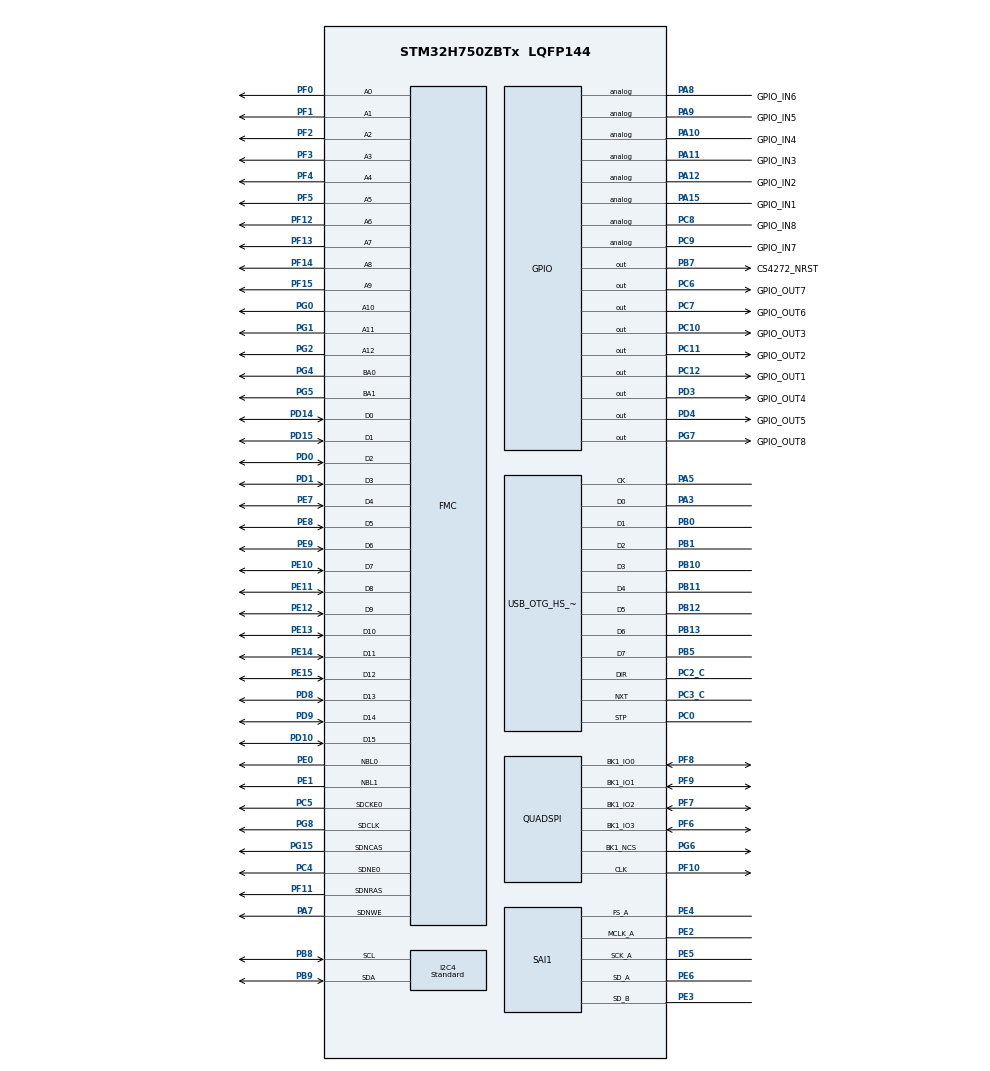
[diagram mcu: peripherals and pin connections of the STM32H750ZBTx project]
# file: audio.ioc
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CORTEX_M7.AccessPermission_S-Cortex_Memory_Protection_Unit_Region1_Settings_S=MPU_REGION_FULL_ACCESS
CORTEX_M7.AccessPermission_Spec=MPU_REGION_FULL_ACCESS
CORTEX_M7.BaseAddress_S-Cortex_Memory_Protection_Unit_Region1_Settings_S=0x24000000 
CORTEX_M7.BaseAddress_Spec=0x90000000
CORTEX_M7.CPU_DCache=Enabled
CORTEX_M7.CPU_ICache=Enabled
CORTEX_M7.DisableExec_S-Cortex_Memory_Protection_Unit_Region1_Settings_S=MPU_INSTRUCTION_ACCESS_ENABLE
CORTEX_M7.DisableExec_Spec=MPU_INSTRUCTION_ACCESS_ENABLE
CORTEX_M7.Enable_S-Cortex_Memory_Protection_Unit_Region1_Settings_S=MPU_REGION_ENABLE
CORTEX_M7.IsBufferable_Spec=MPU_ACCESS_BUFFERABLE
CORTEX_M7.IsCacheable_Spec=MPU_ACCESS_CACHEABLE
CORTEX_M7.IsShareable_S-Cortex_Memory_Protection_Unit_Region1_Settings_S=MPU_ACCESS_SHAREABLE
CORTEX_M7.IsShareable_Spec=MPU_ACCESS_NOT_SHAREABLE
CORTEX_M7.Size_S-Cortex_Memory_Protection_Unit_Region1_Settings_S=MPU_REGION_SIZE_512KB
CORTEX_M7.Size_Spec=MPU_REGION_SIZE_16MB
CORTEX_M7.SubRegionDisable_Spec=0x0
CORTEX_M7.TypeExtField_S-Cortex_Memory_Protection_Unit_Region1_Settings_S=MPU_TEX_LEVEL1
CORTEX_M7.TypeExtField_Spec=MPU_TEX_LEVEL1
CORTEX_M7.default_mode_Activation=1
Dma.Request0=SAI1_B
Dma.Request1=SAI1_A
Dma.SAI1_A.1.Direction=DMA_MEMORY_TO_PERIPH
Dma.SAI1_A.1.EventEnable=DISABLE
Dma.SAI1_A.1.FIFOMode=DMA_FIFOMODE_DISABLE
Dma.SAI1_A.1.Instance=DMA1_Stream1
Dma.SAI1_A.1.MemDataAlignment=DMA_MDATAALIGN_WORD
Dma.SAI1_A.1.MemInc=DMA_MINC_ENABLE
Dma.SAI1_A.1.Mode=DMA_CIRCULAR
Dma.SAI1_A.1.PeriphDataAlignment=DMA_PDATAALIGN_WORD
Dma.SAI1_A.1.PeriphInc=DMA_PINC_DISABLE
Dma.SAI1_A.1.Polarity=HAL_DMAMUX_REQ_GEN_RISING
Dma.SAI1_A.1.Priority=DMA_PRIORITY_VERY_HIGH
Dma.SAI1_A.1.RequestNumber=1
Dma.SAI1_A.1.SignalID=NONE
Dma.SAI1_A.1.SyncEnable=DISABLE
Dma.SAI1_A.1.SyncPolarity=HAL_DMAMUX_SYNC_NO_EVENT
Dma.SAI1_A.1.SyncRequestNumber=1
Dma.SAI1_A.1.SyncSignalID=NONE
Dma.SAI1_B.0.Direction=DMA_PERIPH_TO_MEMORY
Dma.SAI1_B.0.EventEnable=DISABLE
Dma.SAI1_B.0.FIFOMode=DMA_FIFOMODE_DISABLE
Dma.SAI1_B.0.Instance=DMA1_Stream0
Dma.SAI1_B.0.MemDataAlignment=DMA_MDATAALIGN_WORD
Dma.SAI1_B.0.MemInc=DMA_MINC_ENABLE
Dma.SAI1_B.0.Mode=DMA_CIRCULAR
Dma.SAI1_B.0.PeriphDataAlignment=DMA_PDATAALIGN_WORD
Dma.SAI1_B.0.PeriphInc=DMA_PINC_DISABLE
Dma.SAI1_B.0.Polarity=HAL_DMAMUX_REQ_GEN_RISING
Dma.SAI1_B.0.Priority=DMA_PRIORITY_VERY_HIGH
Dma.SAI1_B.0.RequestNumber=1
Dma.SAI1_B.0.SignalID=NONE
Dma.SAI1_B.0.SyncEnable=DISABLE
Dma.SAI1_B.0.SyncPolarity=HAL_DMAMUX_SYNC_NO_EVENT
Dma.SAI1_B.0.SyncRequestNumber=1
Dma.SAI1_B.0.SyncSignalID=NONE
FMC.CASLatency1=FMC_SDRAM_CAS_LATENCY_2
FMC.ColumnBitsNumber1=FMC_SDRAM_COLUMN_BITS_NUM_9
FMC.ExitSelfRefreshDelay1=8
FMC.LoadToActiveDelay1=2
FMC.RCDDelay1=2
FMC.RPDelay1=2
FMC.RPDelay2=2
FMC.ReadBurst1=FMC_SDRAM_RBURST_ENABLE
FMC.ReadBurst2=FMC_SDRAM_RBURST_ENABLE
FMC.ReadPipeDelay1=FMC_SDRAM_RPIPE_DELAY_2
FMC.ReadPipeDelay2=FMC_SDRAM_RPIPE_DELAY_2
FMC.RowCycleDelay1=6
FMC.RowCycleDelay2=6
FMC.SDClockPeriod1=FMC_SDRAM_CLOCK_PERIOD_2
FMC.SDClockPeriod2=FMC_SDRAM_CLOCK_PERIOD_2
FMC.SelfRefreshTime1=5
FMC.WriteRecoveryTime1=3
I2C4.I2C_Speed_Mode=I2C_Standard
I2C4.Speed=100
I2C4.Timing=0x307075B1
Mcu.Family=STM32H7
Mcu.Name=STM32H750ZBTx
Mcu.Package=LQFP144
NVIC.DMA1_Stream0_IRQn=true\:0\:0\:false\:false\:true\:false\:true\:true
NVIC.DMA1_Stream1_IRQn=true\:0\:0\:false\:false\:true\:false\:true\:true
NVIC.OTG_HS_EP1_IN_IRQn=true\:0\:0\:false\:false\:true\:true\:true\:true
NVIC.OTG_HS_EP1_OUT_IRQn=true\:0\:0\:false\:false\:true\:true\:true\:true
NVIC.OTG_HS_IRQn=true\:0\:0\:false\:false\:true\:false\:true\:true
NVIC.PriorityGroup=NVIC_PRIORITYGROUP_4
PA10.GPIO_Label=GPIO_IN4
PA10.Signal=GPIO_Analog
PA11.GPIO_Label=GPIO_IN3
PA11.Signal=GPIO_Analog
PA12.GPIO_Label=GPIO_IN2
PA12.Signal=GPIO_Analog
PA13\ (JTMS/SWDIO).Mode=Trace_Asynchronous_SW
PA13\ (JTMS/SWDIO).Signal=DEBUG_JTMS-SWDIO
PA14\ (JTCK/SWCLK).Mode=Trace_Asynchronous_SW
PA14\ (JTCK/SWCLK).Signal=DEBUG_JTCK-SWCLK
PA15\ (JTDI).GPIO_Label=GPIO_IN1
PA15\ (JTDI).Signal=GPIO_Analog
PA3.Mode=Device_HS
PA3.Signal=USB_OTG_HS_ULPI_D0
PA5.Mode=Device_HS
PA5.Signal=USB_OTG_HS_ULPI_CK
PA7.Signal=FMC_SDNWE
PA8.GPIO_Label=GPIO_IN6
PA8.Signal=GPIO_Analog
PA9.GPIO_Label=GPIO_IN5
PA9.Signal=GPIO_Analog
PB0.Mode=Device_HS
PB0.Signal=USB_OTG_HS_ULPI_D1
PB1.Mode=Device_HS
PB1.Signal=USB_OTG_HS_ULPI_D2
PB10.Mode=Device_HS
PB10.Signal=USB_OTG_HS_ULPI_D3
PB11.Mode=Device_HS
PB11.Signal=USB_OTG_HS_ULPI_D4
PB12.Mode=Device_HS
PB12.Signal=USB_OTG_HS_ULPI_D5
PB13.Mode=Device_HS
PB13.Signal=USB_OTG_HS_ULPI_D6
PB3\ (JTDO/TRACESWO).Mode=Trace_Asynchronous_SW
PB3\ (JTDO/TRACESWO).Signal=DEBUG_JTDO-SWO
PB5.Mode=Device_HS
PB5.Signal=USB_OTG_HS_ULPI_D7
PB7.GPIO_Label=CS4272_NRST
PB7.Signal=GPIO_Output
PB8.Mode=I2C
PB8.Signal=I2C4_SCL
PB9.Mode=I2C
PB9.Signal=I2C4_SDA
PC0.Mode=Device_HS
PC0.Signal=USB_OTG_HS_ULPI_STP
PC10.GPIO_Label=GPIO_OUT3
PC10.Signal=GPIO_Output
PC11.GPIO_Label=GPIO_OUT2
PC11.Signal=GPIO_Output
PC12.GPIO_Label=GPIO_OUT1
PC12.Signal=GPIO_Output
PC2_C.Mode=Device_HS
PC2_C.Signal=USB_OTG_HS_ULPI_DIR
PC3_C.Mode=Device_HS
PC3_C.Signal=USB_OTG_HS_ULPI_NXT
PC4.Mode=SdramChipSelect1_1
PC4.Signal=FMC_SDNE0
PC5.Mode=SdramChipSelect1_1
PC5.Signal=FMC_SDCKE0
PC6.GPIO_Label=GPIO_OUT7
PC6.Signal=GPIO_Output
PC7.GPIO_Label=GPIO_OUT6
PC7.Signal=GPIO_Output
PC8.GPIO_Label=GPIO_IN8
PC8.Signal=GPIO_Analog
PC9.GPIO_Label=GPIO_IN7
PC9.Signal=GPIO_Analog
PD0.Signal=FMC_D2_DA2
PD1.Signal=FMC_D3_DA3
PD10.Signal=FMC_D15_DA15
PD14.Signal=FMC_D0_DA0
PD15.Signal=FMC_D1_DA1
PD3.GPIO_Label=GPIO_OUT4
PD3.Signal=GPIO_Output
PD4.GPIO_Label=GPIO_OUT5
PD4.Signal=GPIO_Output
PD8.Signal=FMC_D13_DA13
PD9.Signal=FMC_D14_DA14
PE0.Signal=FMC_NBL0
PE1.Signal=FMC_NBL1
PE10.Signal=FMC_D7_DA7
PE11.Signal=FMC_D8_DA8
PE12.Signal=FMC_D9_DA9
PE13.Signal=FMC_D10_DA10
PE14.Signal=FMC_D11_DA11
PE15.Signal=FMC_D12_DA12
PE2.GPIO_Mode=GPIO_MODE_AF_PP
PE2.GPIO_Speed=GPIO_SPEED_FREQ_VERY_HIGH
PE2.Mode=SAI_A_MasterWithClock
PE2.Signal=SAI1_MCLK_A
PE3.GPIO_Mode=GPIO_MODE_AF_PP
PE3.GPIO_Speed=GPIO_SPEED_FREQ_VERY_HIGH
PE3.Mode=SAI_B_SyncSlave
PE3.Signal=SAI1_SD_B
PE4.GPIO_Mode=GPIO_MODE_AF_PP
PE4.GPIO_Speed=GPIO_SPEED_FREQ_VERY_HIGH
PE4.Mode=SAI_A_MasterWithClock
PE4.Signal=SAI1_FS_A
PE5.GPIO_Mode=GPIO_MODE_AF_PP
PE5.GPIO_Speed=GPIO_SPEED_FREQ_VERY_HIGH
PE5.Mode=SAI_A_MasterWithClock
PE5.Signal=SAI1_SCK_A
PE6.GPIO_Mode=GPIO_MODE_AF_PP
PE6.GPIO_Speed=GPIO_SPEED_FREQ_VERY_HIGH
PE6.Mode=SAI_A_MasterWithClock
PE6.Signal=SAI1_SD_A
PE7.Signal=FMC_D4_DA4
PE8.Signal=FMC_D5_DA5
PE9.Signal=FMC_D6_DA6
PF0.Signal=FMC_A0
PF1.Signal=FMC_A1
PF10.GPIO_Speed=GPIO_SPEED_FREQ_VERY_HIGH
PF10.Mode=Single Bank 1
PF10.Signal=QUADSPI_CLK
PF11.Signal=FMC_SDNRAS
PF12.Signal=FMC_A6
PF13.Signal=FMC_A7
PF14.Signal=FMC_A8
PF15.Signal=FMC_A9
PF2.Signal=FMC_A2
PF3.Signal=FMC_A3
PF4.Signal=FMC_A4
PF5.Signal=FMC_A5
PF6.GPIO_Speed=GPIO_SPEED_FREQ_VERY_HIGH
PF6.Mode=Single Bank 1
PF6.Signal=QUADSPI_BK1_IO3
PF7.GPIO_Speed=GPIO_SPEED_FREQ_VERY_HIGH
PF7.Mode=Single Bank 1
PF7.Signal=QUADSPI_BK1_IO2
PF8.GPIO_Speed=GPIO_SPEED_FREQ_VERY_HIGH
PF8.Mode=Single Bank 1
PF8.Signal=QUADSPI_BK1_IO0
PF9.GPIO_Speed=GPIO_SPEED_FREQ_VERY_HIGH
PF9.Mode=Single Bank 1
PF9.Signal=QUADSPI_BK1_IO1
PG0.Signal=FMC_A10
PG1.Signal=FMC_A11
PG15.Signal=FMC_SDNCAS
PG2.Signal=FMC_A12
PG4.Signal=FMC_A14_BA0
PG5.Signal=FMC_A15_BA1
PG6.GPIO_Speed=GPIO_SPEED_FREQ_VERY_HIGH
PG6.Mode=Single Bank 1
PG6.Signal=QUADSPI_BK1_NCS
PG7.GPIO_Label=GPIO_OUT8
PG7.Signal=GPIO_Output
PG8.Signal=FMC_SDCLK
PH0-OSC_IN\ (PH0).Mode=HSE-External-Clock-Source
PH0-OSC_IN\ (PH0).Signal=RCC_OSC_IN
ProjectManager.HeapSize=0x200
ProjectManager.StackSize=0x400
ProjectManager.TargetToolchain=STM32CubeIDE
QUADSPI.ChipSelectHighTime=QSPI_CS_HIGH_TIME_2_CYCLE
QUADSPI.ClockPrescaler=2
QUADSPI.FifoThreshold=4
QUADSPI.FlashSize=23
QUADSPI.SampleShifting=QSPI_SAMPLE_SHIFTING_HALFCYCLE
RCC.ADCFreq_Value=100000000
RCC.APB1Freq_Value=120000000
RCC.APB2Freq_Value=120000000
RCC.APB3Freq_Value=120000000
RCC.APB4Freq_Value=120000000
RCC.CortexFreq_Value=480000000
RCC.D1PPRE=RCC_APB3_DIV2
RCC.D2PPRE1=RCC_APB1_DIV2
RCC.D2PPRE2=RCC_APB2_DIV2
RCC.D3PPRE=RCC_APB4_DIV2
RCC.DIVM1=5
RCC.DIVM2=2
RCC.DIVM3=5
RCC.DIVN1=192
RCC.DIVN2=16
RCC.DIVN3=49
RCC.DIVP3=20
RCC.DIVQ1=15
RCC.DIVQ3=5
RCC.DIVR2=1
RCC.DIVR3=30
RCC.FMCCLockSelection=RCC_FMCCLKSOURCE_PLL2
RCC.HCLKFreq_Value=240000000
RCC.HPRE=RCC_HCLK_DIV2
RCC.HSE_VALUE=25000000
RCC.PLL2FRACN=0
RCC.PLL3FRACN=1246
RCC.PLLFRACN=0
RCC.QSPICLockSelection=RCC_QSPICLKSOURCE_PLL2
RCC.SAI1CLockSelection=RCC_SAI1CLKSOURCE_PLL3
RCC.SYSCLKFreq_VALUE=480000000
RCC.SYSCLKSource=RCC_SYSCLKSOURCE_PLLCLK
RCC.USBFreq_Value=64000000
SAI1.AudioFrequency-SAI_A_MasterWithClock=SAI_AUDIO_FREQUENCY_48K
SAI1.BasicDataSize-SAI_A_MasterWithClock=SAI_PROTOCOL_DATASIZE_24BIT
SAI1.BasicDataSize-SAI_B_SyncSlave=SAI_PROTOCOL_DATASIZE_24BIT
SAI1.ErrorAudioFreq-SAI_A_MasterWithClock=0.0 %
SAI1.FIFOThreshold-SAI_A_MasterWithClock=SAI_FIFOTHRESHOLD_EMPTY
SAI1.FIFOThreshold-SAI_B_SyncSlave=SAI_FIFOTHRESHOLD_EMPTY
SAI1.InitProtocol-SAI_A_MasterWithClock=Enable
SAI1.InitProtocol-SAI_B_SyncSlave=Enable
SAI1.Instance-SAI_A_MasterWithClock=SAI$Index_Block_A
SAI1.Instance-SAI_B_SyncSlave=SAI$Index_Block_B
SAI1.MClockEnable-SAI_A_MasterWithClock=SAI_MASTERCLOCK_ENABLE
SAI1.NoDivider-SAI_A_MasterWithClock=SAI_MCK_OVERSAMPLING_DISABLE
SAI1.OutputDrive-SAI_A_MasterWithClock=SAI_OUTPUTDRIVE_DISABLE
SAI1.RealAudioFreq-SAI_A_MasterWithClock=48.0 KHz
SAI1.VirtualMode-SAI_A_MasterWithClock=VM_MASTER
SAI1.VirtualMode-SAI_B_SyncSlave=VM_SLAVE
SAI1.VirtualProtocol-SAI_A_BASIC=VM_BASIC_PROTOCOL
SAI1.VirtualProtocol-SAI_B_BASIC=VM_BASIC_PROTOCOL
SH.FMC_A0.0=FMC_A0,13b-sda1
SH.FMC_A1.0=FMC_A1,13b-sda1
SH.FMC_A10.0=FMC_A10,13b-sda1
SH.FMC_A11.0=FMC_A11,13b-sda1
SH.FMC_A12.0=FMC_A12,13b-sda1
SH.FMC_A14_BA0.0=FMC_BA0,FourSdramBanks1
SH.FMC_A15_BA1.0=FMC_BA1,FourSdramBanks1
SH.FMC_A2.0=FMC_A2,13b-sda1
SH.FMC_A3.0=FMC_A3,13b-sda1
SH.FMC_A4.0=FMC_A4,13b-sda1
SH.FMC_A5.0=FMC_A5,13b-sda1
SH.FMC_A6.0=FMC_A6,13b-sda1
SH.FMC_A7.0=FMC_A7,13b-sda1
SH.FMC_A8.0=FMC_A8,13b-sda1
SH.FMC_A9.0=FMC_A9,13b-sda1
SH.FMC_D0_DA0.0=FMC_D0,sd-16b-d1
SH.FMC_D10_DA10.0=FMC_D10,sd-16b-d1
SH.FMC_D11_DA11.0=FMC_D11,sd-16b-d1
SH.FMC_D12_DA12.0=FMC_D12,sd-16b-d1
SH.FMC_D13_DA13.0=FMC_D13,sd-16b-d1
SH.FMC_D14_DA14.0=FMC_D14,sd-16b-d1
SH.FMC_D15_DA15.0=FMC_D15,sd-16b-d1
SH.FMC_D1_DA1.0=FMC_D1,sd-16b-d1
SH.FMC_D2_DA2.0=FMC_D2,sd-16b-d1
SH.FMC_D3_DA3.0=FMC_D3,sd-16b-d1
SH.FMC_D4_DA4.0=FMC_D4,sd-16b-d1
SH.FMC_D5_DA5.0=FMC_D5,sd-16b-d1
SH.FMC_D6_DA6.0=FMC_D6,sd-16b-d1
SH.FMC_D7_DA7.0=FMC_D7,sd-16b-d1
SH.FMC_D8_DA8.0=FMC_D8,sd-16b-d1
SH.FMC_D9_DA9.0=FMC_D9,sd-16b-d1
SH.FMC_NBL0.0=FMC_NBL0,Sd2ByteEnable1
SH.FMC_NBL1.0=FMC_NBL1,Sd2ByteEnable1
SH.FMC_SDCLK.0=FMC_SDCLK,13b-sda1
SH.FMC_SDNCAS.0=FMC_SDNCAS,13b-sda1
SH.FMC_SDNRAS.0=FMC_SDNRAS,13b-sda1
SH.FMC_SDNWE.0=FMC_SDNWE,13b-sda1
USB_DEVICE.CLASS_NAME_HS=MSC
USB_DEVICE.VirtualMode-MSC_HS=Msc
USB_DEVICE.VirtualModeHS=Msc_HS
USB_OTG_HS.VirtualMode-Device_HS=Device_HS
USB_OTG_HS.dma_enable-Device_HS=ENABLE
VP_MEMORYMAP_VS_MEMORYMAP.Mode=CurAppReg
VP_SAI1_VP_$IpInstance_SAIA_SAI_BASIC.Mode=SAI_A_BASIC
VP_SAI1_VP_$IpInstance_SAIB_SAI_BASIC.Mode=SAI_B_BASIC
VP_USB_DEVICE_VS_USB_DEVICE_MSC_HS.Mode=MSC_HS
board=custom

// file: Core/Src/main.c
/* USER CODE BEGIN Header */
/**
  ******************************************************************************
  * @file           : main.c
  * @brief          : Main program body
  ******************************************************************************
  * @attention
  *
  * Copyright (c) 2026 STMicroelectronics.
  * All rights reserved.
  *
  * This software is licensed under terms that can be found in the LICENSE file
  * in the root directory of this software component.
  * If no LICENSE file comes with this software, it is provided AS-IS.
  *
  ******************************************************************************
  */
/* USER CODE END Header */
#include "main.h"
#include "dma.h"
#include "i2c.h"
#include "quadspi.h"
#include "sai.h"
#include "usb_device.h"
#include "gpio.h"
#include "fmc.h"

/* USER CODE BEGIN Includes */
#include "cs4272.h"
#include "w9825g6kh6.h"
/* USER CODE END Includes */

void SystemClock_Config(void);
void PeriphCommonClock_Config(void);
static void MPU_Config(void);

int main(void)
{

  /* USER CODE BEGIN 1 */

  /* disabled by the boot loader */
  __enable_irq();

  /* USER CODE END 1 */

  /* MPU Configuration--------------------------------------------------------*/
  MPU_Config();

  /* Enable the CPU Cache */

  /* Enable I-Cache---------------------------------------------------------*/
  SCB_EnableICache();

  /* Enable D-Cache---------------------------------------------------------*/
  SCB_EnableDCache();

  /* MCU Configuration--------------------------------------------------------*/

  /* Reset of all peripherals, Initializes the Flash interface and the Systick. */
  HAL_Init();

  /* Configure the system clock */
  SystemClock_Config();

  /* Configure the peripherals common clocks */
  PeriphCommonClock_Config();

  /* Initialize all configured peripherals */
  MX_GPIO_Init();
  MX_DMA_Init();
  MX_FMC_Init();
  MX_I2C4_Init();
  MX_SAI1_Init();
  MX_USB_DEVICE_Init();
  //MX_QUADSPI_Init();
  /* USER CODE BEGIN 2 */

  FMC_Init();
  SDRAM_Test();

  __HAL_RCC_SAI1_CLK_ENABLE();
  __HAL_SAI_ENABLE(&hsai_BlockA1);

  HAL_Delay(10);

  if (CS4272_Init() != HAL_OK) {
      Error_Handler();
  }

  if (HAL_SAI_Receive_DMA(&hsai_BlockB1, (uint8_t *)rx_buffer, BUFFER_SIZE) != HAL_OK) {
      Error_Handler();
  }

  if (HAL_SAI_Transmit_DMA(&hsai_BlockA1, (uint8_t *)tx_buffer, BUFFER_SIZE) != HAL_OK) {
      Error_Handler();
  }

  /* USER CODE END 2 */

  /* Infinite loop */
  while (1)
  {

  }
}

void SystemClock_Config(void)
{
  RCC_OscInitTypeDef RCC_OscInitStruct = {0};
  RCC_ClkInitTypeDef RCC_ClkInitStruct = {0};

  /** Supply configuration update enable
  */
  HAL_PWREx_ConfigSupply(PWR_LDO_SUPPLY);

  /** Configure the main internal regulator output voltage
  */
  __HAL_PWR_VOLTAGESCALING_CONFIG(PWR_REGULATOR_VOLTAGE_SCALE0);

  while(!__HAL_PWR_GET_FLAG(PWR_FLAG_VOSRDY)) {}

  /** Initializes the RCC Oscillators according to the specified parameters
  * in the RCC_OscInitTypeDef structure.
  */
  RCC_OscInitStruct.OscillatorType = RCC_OSCILLATORTYPE_HSE;
  RCC_OscInitStruct.HSEState = RCC_HSE_BYPASS;
  RCC_OscInitStruct.PLL.PLLState = RCC_PLL_ON;
  RCC_OscInitStruct.PLL.PLLSource = RCC_PLLSOURCE_HSE;
  RCC_OscInitStruct.PLL.PLLM = 5;
  RCC_OscInitStruct.PLL.PLLN = 192;
  RCC_OscInitStruct.PLL.PLLP = 2;
  RCC_OscInitStruct.PLL.PLLQ = 15;
  RCC_OscInitStruct.PLL.PLLR = 2;
  RCC_OscInitStruct.PLL.PLLRGE = RCC_PLL1VCIRANGE_2;
  RCC_OscInitStruct.PLL.PLLVCOSEL = RCC_PLL1VCOWIDE;
  RCC_OscInitStruct.PLL.PLLFRACN = 0;
  if (HAL_RCC_OscConfig(&RCC_OscInitStruct) != HAL_OK)
  {
    Error_Handler();
  }

  /** Initializes the CPU, AHB and APB buses clocks
  */
  RCC_ClkInitStruct.ClockType = RCC_CLOCKTYPE_HCLK|RCC_CLOCKTYPE_SYSCLK
                              |RCC_CLOCKTYPE_PCLK1|RCC_CLOCKTYPE_PCLK2
                              |RCC_CLOCKTYPE_D3PCLK1|RCC_CLOCKTYPE_D1PCLK1;
  RCC_ClkInitStruct.SYSCLKSource = RCC_SYSCLKSOURCE_PLLCLK;
  RCC_ClkInitStruct.SYSCLKDivider = RCC_SYSCLK_DIV1;
  RCC_ClkInitStruct.AHBCLKDivider = RCC_HCLK_DIV2;
  RCC_ClkInitStruct.APB3CLKDivider = RCC_APB3_DIV2;
  RCC_ClkInitStruct.APB1CLKDivider = RCC_APB1_DIV2;
  RCC_ClkInitStruct.APB2CLKDivider = RCC_APB2_DIV2;
  RCC_ClkInitStruct.APB4CLKDivider = RCC_APB4_DIV2;

  if (HAL_RCC_ClockConfig(&RCC_ClkInitStruct, FLASH_LATENCY_4) != HAL_OK)
  {
    Error_Handler();
  }
}

/* USER CODE BEGIN 4 */

void PeriphCommonClock_Config(void)
{
  RCC_PeriphCLKInitTypeDef PeriphClkInitStruct = {0};

  /** Initializes the peripherals clock
  */
  PeriphClkInitStruct.PeriphClockSelection = RCC_PERIPHCLK_SAI1;
  PeriphClkInitStruct.PLL3.PLL3M = 5;
  PeriphClkInitStruct.PLL3.PLL3N = 49;
  PeriphClkInitStruct.PLL3.PLL3P = 20;
  PeriphClkInitStruct.PLL3.PLL3Q = 5;
  PeriphClkInitStruct.PLL3.PLL3R = 30;
  PeriphClkInitStruct.PLL3.PLL3RGE = RCC_PLL3VCIRANGE_2;
  PeriphClkInitStruct.PLL3.PLL3VCOSEL = RCC_PLL3VCOWIDE;
  PeriphClkInitStruct.PLL3.PLL3FRACN = 1246;
  PeriphClkInitStruct.Sai1ClockSelection = RCC_SAI1CLKSOURCE_PLL3;
  if (HAL_RCCEx_PeriphCLKConfig(&PeriphClkInitStruct) != HAL_OK)
  {
    Error_Handler();
  }
}

/* USER CODE END 4 */

 /* MPU Configuration */

void MPU_Config(void)
{
  MPU_Region_InitTypeDef MPU_InitStruct = {0};

  /* Disables the MPU */
  HAL_MPU_Disable();

  /** Initializes and configures the Region and the memory to be protected
  */
  MPU_InitStruct.Enable = MPU_REGION_ENABLE;
  MPU_InitStruct.Number = MPU_REGION_NUMBER0;
  MPU_InitStruct.BaseAddress = 0x90000000;
  MPU_InitStruct.Size = MPU_REGION_SIZE_16MB;
  MPU_InitStruct.SubRegionDisable = 0x0;
  MPU_InitStruct.TypeExtField = MPU_TEX_LEVEL1;
  MPU_InitStruct.AccessPermission = MPU_REGION_FULL_ACCESS;
  MPU_InitStruct.DisableExec = MPU_INSTRUCTION_ACCESS_ENABLE;
  MPU_InitStruct.IsShareable = MPU_ACCESS_NOT_SHAREABLE;
  MPU_InitStruct.IsCacheable = MPU_ACCESS_CACHEABLE;
  MPU_InitStruct.IsBufferable = MPU_ACCESS_BUFFERABLE;

  HAL_MPU_ConfigRegion(&MPU_InitStruct);

  /** Initializes and configures the Region and the memory to be protected
  */
  MPU_InitStruct.Number = MPU_REGION_NUMBER1;
  MPU_InitStruct.BaseAddress = 0x24000000 ;
  MPU_InitStruct.Size = MPU_REGION_SIZE_512KB;
  MPU_InitStruct.IsShareable = MPU_ACCESS_SHAREABLE;
  MPU_InitStruct.IsCacheable = MPU_ACCESS_NOT_CACHEABLE;
  MPU_InitStruct.IsBufferable = MPU_ACCESS_NOT_BUFFERABLE;

  HAL_MPU_ConfigRegion(&MPU_InitStruct);
  /* Enables the MPU */
  HAL_MPU_Enable(MPU_PRIVILEGED_DEFAULT);

}

void Error_Handler(void)
{
  /* USER CODE BEGIN Error_Handler_Debug */
  /* User can add his own implementation to report the HAL error return state */
  while (1)
  {
      HAL_GPIO_WritePin(GPIOC, GPIO_PIN_12, GPIO_PIN_SET);

      HAL_Delay(500);

      HAL_GPIO_WritePin(GPIOC, GPIO_PIN_12, GPIO_PIN_RESET);

      HAL_Delay(500);
  }
  /* USER CODE END Error_Handler_Debug */
}
